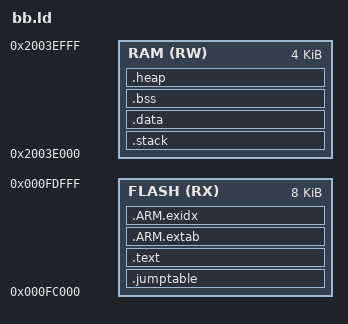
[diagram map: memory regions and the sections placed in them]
/***** AUTOGENERATED *****/

/* box calls */
__box_bobbox_write = 0x1e000000 + 4*4 + 1*2 + 1;
alicebox_getpubkey = 0x1e000000 + 16*4 + 1*2 + 1;
sys_rsa_freekey  = 0x1e000000 + 28*4 + 1*2 + 1;
sys_rsa_fromprivkey = 0x1e000000 + 36*4 + 1*2 + 1;
sys_rsa_frompubkey = 0x1e000000 + 44*4 + 1*2 + 1;
sys_rsa_genkey   = 0x1e000000 + 52*4 + 1*2 + 1;
sys_rsa_getprivkey = 0x1e000000 + 60*4 + 1*2 + 1;
sys_rsa_getpubkey = 0x1e000000 + 68*4 + 1*2 + 1;
sys_rsa_pkcs1_decrypt = 0x1e000000 + 76*4 + 1*2 + 1;
sys_rsa_pkcs1_encrypt = 0x1e000000 + 84*4 + 1*2 + 1;
sys_send_to_alice = 0x1e000000 + 92*4 + 1*2 + 1;

/* special box triggers */
__box_ret        = 0x1f000000 + 1;
__box_abort      = 0x1f000000 + 1*4 + 1;
__box_write      = __box_bobbox_write;

/* overridable constants */
__stack_min      = DEFINED(__stack_min) ? __stack_min : 0x00000800;
__heap_min       = DEFINED(__heap_min) ? __heap_min : 0x00000000;

MEMORY {
    FLASH            (RX ) : ORIGIN = 0x000fc000, LENGTH = 0x00002000
    RAM              (RW ) : ORIGIN = 0x2003e000, LENGTH = 0x00001000
}

SECTIONS {
    /* FLASH sections */
    . = ORIGIN(FLASH);
    . = ALIGN(4);
    __jumptable_start = .;
    .jumptable . : {
        __jumptable = .;
        KEEP(*(.jumptable))
    } > FLASH
    . = ALIGN(4);
    __jumptable_end = .;

    . = ALIGN(4);
    __text_start = .;
    .text . : {
        *(.text*)
        *(.rodata*)
        *(.glue_7*)
        *(.glue_7t*)
        *(.eh_frame*)

        KEEP(*(SORT_NONE(.init)))
        KEEP(*(SORT_NONE(.init*)))
        KEEP(*(SORT_NONE(.fini)))
        KEEP(*(SORT_NONE(.fini*)))

        . = ALIGN(4);
        PROVIDE_HIDDEN(__preinit_array_start = .);
        KEEP(*(SORT(.preinit_array)))
        PROVIDE_HIDDEN(__preinit_array_end = .);

        . = ALIGN(4);
        PROVIDE_HIDDEN(__init_array_start = .);
        KEEP(*(SORT(.init_array.*)))
        PROVIDE_HIDDEN(__init_array_end = .);

        . = ALIGN(4);
        PROVIDE_HIDDEN(__fini_array_start = .);
        KEEP(*(SORT(.fini_array.*)))
        PROVIDE_HIDDEN(__fini_array_end = .);

        KEEP(*crtbegin.o(.ctors))
        KEEP(*crtbegin?.o(.ctors))
        KEEP(*(EXCLUDE_FILE(*crtend?.o *crtend.o) .ctors))
        KEEP(*(SORT(.ctors.*)))

        KEEP(*crtbegin.o(.dtors))
        KEEP(*crtbegin?.o(.dtors))
        KEEP(*(EXCLUDE_FILE(*crtend?.o *crtend.o) .dtors))
        KEEP(*(SORT(.dtors.*)))
    } > FLASH
    . = ALIGN(4);
    __text_end = .;

    __extab_start = .;
    .ARM.extab : {
        *(.ARM.extab* .gnu.linkonce.armextab.*)
    } > FLASH
    __extab_end = .;

    __exidx_start = .;
    .ARM.exidx : {
        *(.ARM.exidx* .gnu.linkonce.armexidx.*)
    } > FLASH
    __exidx_end = .;

    . = ALIGN(4);
    __data_init_start = .;

    /* RAM sections */
    . = ORIGIN(RAM);
    . = ALIGN(4);
    __stack_start = .;
    .stack . (NOLOAD) : {
        . = .;
    } > RAM
    . += __stack_min;
    . = ALIGN(4);
    __stack_end = .;

    . = ALIGN(4);
    __data_start = .;
    .data . : AT(__data_init_start) {
        *(.data*)
    } > RAM
    . = ALIGN(4);
    __data_end = .;

    __data_init_end = LOADADDR(.data) + SIZEOF(.data);
    ASSERT(__data_init_end <= ORIGIN(FLASH) + LENGTH(FLASH),
        "Not enough memory in FLASH for data init")

    . = ALIGN(4);
    __bss_start = .;
    __bss_start__ = .;
    .bss . (NOLOAD) : {
        *(.bss*)
        *(COMMON)
    } > RAM
    . = ALIGN(4);
    __bss_end = .;
    __bss_end__ = .;

    . = ALIGN(4);
    __heap_start = .;
    __end__ = .;
    PROVIDE(end = .);
    .heap . (NOLOAD) : {
        . = .;
    } > RAM
    . = ORIGIN(RAM) + LENGTH(RAM);
    . = ALIGN(4);
    __heap_end = .;
    __heap_limit = .;

    ASSERT(__heap_end - __heap_start > __heap_min,
        "Not enough memory in RAM for heap")
}

